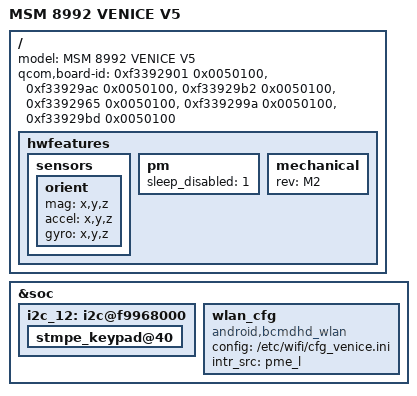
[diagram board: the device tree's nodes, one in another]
/* Copyright (C) 2015 BlackBerry Limited. All rights reserved.
 * Copyright (c) 2014, The Linux Foundation. All rights reserved.
 *
 * This program is free software; you can redistribute it and/or modify
 * it under the terms of the GNU General Public License version 2 and
 * only version 2 as published by the Free Software Foundation.
 *
 * This program is distributed in the hope that it will be useful,
 * but WITHOUT ANY WARRANTY; without even the implied warranty of
 * MERCHANTABILITY or FITNESS FOR A PARTICULAR PURPOSE.  See the
 * GNU General Public License for more details.
 */

/dts-v1/;

#include "msm8992-pm8994-bbry-venice.dtsi"
#include "msm8992-pm8994-bbry-venice-pinmux-v5.dtsi"
#include "msm8992-pm8994-bbry-venice-sensors.dtsi"

/ {
	model = "MSM 8992 VENICE V5";
	qcom,board-id = <0xf3392901 0x0050100>,
			<0xf33929ac 0x0050100>,
			<0xf33929b2 0x0050100>,
			<0xf3392965 0x0050100>,
			<0xf339299a 0x0050100>,
			<0xf33929bd 0x0050100>;

	hwfeatures {
		sensors {
			orient {
				mag = "x,y,z";
				accel = "x,y,z";
				gyro = "x,y,z";
			};
		};
		pm {
			sleep_disabled = "1";
		};
		mechanical {
			rev = "M2";
		};
	};

};

&soc {
	i2c_12: i2c@f9968000 {
		stmpe_keypad@40 {
			/delete-property/ st,reset_det_gpio;
			/delete-property/ st,keypad-rst-int;
		};
	};

	wlan_cfg {
		compatible = "android,bcmdhd_wlan";
		config = "/etc/wifi/cfg_venice.ini";
		/* interrupt source is either "pme_l" or "gpio0" */
		intr_src = "pme_l";
	};
};
